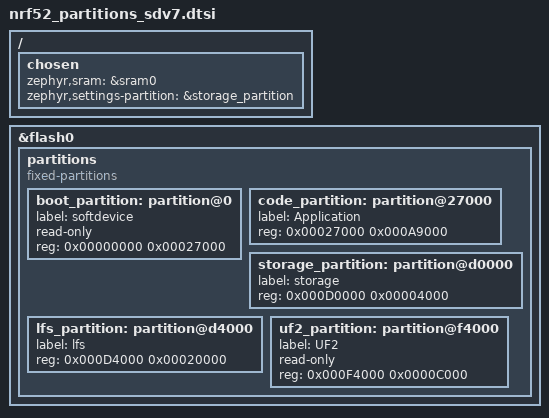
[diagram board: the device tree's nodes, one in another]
/*
 * SPDX-License-Identifier: MIT
 * nRF52840 partition layout — SoftDevice s140 v7 + UF2 bootloader
 *
 * ┌──────────────────────────────────────────────────────────────────┐
 * │  ZephCore Board DTS Include Guide — Storage & Partitions        │
 * ├──────────────────────────────────────────────────────────────────┤
 * │                                                                  │
 * │  PLATFORM          INCLUDE THIS FILE                            │
 * │  ────────          ──────────────────                           │
 * │  nRF52 + SD v7     nrf52_partitions_sdv7.dtsi  ← THIS FILE     │
 * │  nRF52 + SD v6     nrf52_partitions_sdv6.dtsi                   │
 * │  ESP32 / MG24 /    filesystem.dtsi  (single /lfs automount)     │
 * │    nRF54L                                                       │
 * │                                                                  │
 * │  OPTIONAL ADD-ON   WHEN TO USE                                  │
 * │  ────────────────  ──────────                                   │
 * │  qspi-ext.dtsi     Board has QSPI flash → adds /ext mount      │
 * │                     (contacts/channels/blobs migrate to QSPI)   │
 * │                     Requires board to define qspi_storage_part  │
 * │                                                                  │
 * │  sensors-i2c.dtsi   Board has I2C sensors (auto-detect)         │
 * │                                                                  │
 * │  HOW TO IDENTIFY YOUR SOFTDEVICE VERSION:                       │
 * │  - SD v7: Application starts at 0x27000 (156KB reserved)       │
 * │    Boards: T1000-E, Ikoka Nano 30dBm, Wio Tracker L1           │
 * │  - SD v6: Application starts at 0x26000 (152KB reserved)       │
 * │    Boards: RAK4631, ThinkNode M6                                │
 * │                                                                  │
 * │  USAGE IN BOARD DTS (if base includes nrf52840_partition.dtsi): │
 * │    /delete-node/ &boot_partition;                               │
 * │    /delete-node/ &slot0_partition;                              │
 * │    /delete-node/ &slot1_partition;                              │
 * │    /delete-node/ &storage_partition;                            │
 * │    #include "../../common/nrf52_partitions_sdv7.dtsi"           │
 * │                                                                  │
 * │  CHOSEN NODE:                                                   │
 * │    zephyr,code-partition = &code_partition;                     │
 * │    zephyr,settings-partition = &storage_partition; (NVS bonds) │
 * │                                                                  │
 * │  QSPI ADD-ON (if board has external QSPI flash):               │
 * │    In board.overlay:                                            │
 * │      #include "../../common/qspi-ext.dtsi"                     │
 * │                                                                  │
 * └──────────────────────────────────────────────────────────────────┘
 *
 * Memory map (1MB internal flash):
 *   0x00000 - 0x27000  (156KB) SoftDevice s140 v7 (reserved)
 *   0x27000 - 0xD0000  (676KB) Application
 *   0xD0000 - 0xD4000  (16KB)  NVS settings/bonds (storage_partition)
 *   0xD4000 - 0xF4000  (128KB) LittleFS (/lfs automount)
 *   0xF4000 - 0x100000 (48KB)  UF2 bootloader (reserved)
 */

/ {
	chosen {
		/* nRF52840 SoC DTSI defines sram0 but does NOT set zephyr,sram
		 * in chosen. The upstream nrf52840_partition.dtsi provides it,
		 * but custom boards that include this file directly (without
		 * nrf52840_partition.dtsi) would get RAM = 0 in the linker
		 * script, causing "region RAM overflowed" on the first build.
		 * Set it here so all boards using this DTSI get it for free. */
		zephyr,sram = &sram0;
		/* BLE bonds live in the NVS storage_partition, not the /lfs
		 * settings file — see boards/common/nrf52_common.conf. */
		zephyr,settings-partition = &storage_partition;
	};
};

&flash0 {
	partitions {
		compatible = "fixed-partitions";
		#address-cells = <1>;
		#size-cells = <1>;

		/* SoftDevice s140 v7 — 156KB (reserved, managed by bootloader) */
		boot_partition: partition@0 {
			label = "softdevice";
			read-only;
			reg = <0x00000000 0x00027000>;
		};

		/* Application — 676KB (16KB trimmed from the top for the NVS
		 * settings partition below; lfs is left byte-identical). */
		code_partition: partition@27000 {
			label = "Application";
			reg = <0x00027000 0x000A9000>;
		};

		/* BLE bond store — 16KB NVS (Zephyr settings backend).  Carved
		 * from the END of the app slot so lfs_partition keeps the same
		 * offset+size: identity/prefs/contacts in /lfs survive this change.
		 * Isolating bonds here stops settings-write churn from corrupting
		 * the /lfs LittleFS volume.  Label "storage" so the existing
		 * factory-reset path (formatFileSystem) erases it too. */
		storage_partition: partition@d0000 {
			label = "storage";
			reg = <0x000D0000 0x00004000>;
		};

		/* LittleFS — 128KB: identity, prefs, contacts, channels, blobs */
		lfs_partition: partition@d4000 {
			label = "lfs";
			reg = <0x000D4000 0x00020000>;
		};

		/* UF2 bootloader — 48KB (reserved) */
		uf2_partition: partition@f4000 {
			label = "UF2";
			read-only;
			reg = <0x000F4000 0x0000C000>;
		};
	};
};

/* LittleFS /lfs automount */
#include "filesystem.dtsi"
